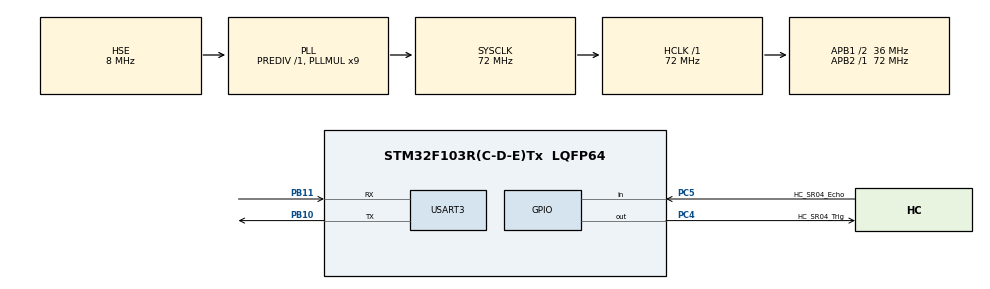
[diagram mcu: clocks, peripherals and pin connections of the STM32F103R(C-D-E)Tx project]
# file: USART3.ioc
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Dma.Request0=USART3_RX
Dma.Request1=USART3_TX
Dma.USART3_RX.0.Direction=DMA_PERIPH_TO_MEMORY
Dma.USART3_RX.0.Instance=DMA1_Channel3
Dma.USART3_RX.0.MemDataAlignment=DMA_MDATAALIGN_BYTE
Dma.USART3_RX.0.MemInc=DMA_MINC_ENABLE
Dma.USART3_RX.0.Mode=DMA_CIRCULAR
Dma.USART3_RX.0.PeriphDataAlignment=DMA_PDATAALIGN_BYTE
Dma.USART3_RX.0.PeriphInc=DMA_PINC_DISABLE
Dma.USART3_RX.0.Priority=DMA_PRIORITY_LOW
Dma.USART3_TX.1.Direction=DMA_MEMORY_TO_PERIPH
Dma.USART3_TX.1.Instance=DMA1_Channel2
Dma.USART3_TX.1.MemDataAlignment=DMA_MDATAALIGN_BYTE
Dma.USART3_TX.1.MemInc=DMA_MINC_ENABLE
Dma.USART3_TX.1.Mode=DMA_CIRCULAR
Dma.USART3_TX.1.PeriphDataAlignment=DMA_PDATAALIGN_BYTE
Dma.USART3_TX.1.PeriphInc=DMA_PINC_DISABLE
Dma.USART3_TX.1.Priority=DMA_PRIORITY_LOW
Mcu.Family=STM32F1
Mcu.Name=STM32F103R(C-D-E)Tx
Mcu.Package=LQFP64
NVIC.DMA1_Channel2_IRQn=true\:0\:0\:false\:false\:true\:false\:true
NVIC.DMA1_Channel3_IRQn=true\:0\:0\:false\:false\:true\:false\:true
NVIC.PriorityGroup=NVIC_PRIORITYGROUP_4
NVIC.TIM2_IRQn=true\:0\:0\:false\:false\:true\:true\:true
PA13.Mode=Serial_Wire
PA13.Signal=SYS_JTMS-SWDIO
PA14.Mode=Serial_Wire
PA14.Signal=SYS_JTCK-SWCLK
PB10.Mode=Asynchronous
PB10.Signal=USART3_TX
PB11.Mode=Asynchronous
PB11.Signal=USART3_RX
PC4.GPIO_Label=HC_SR04_Trig
PC4.GPIO_PuPd=GPIO_PULLDOWN
PC4.GPIO_Speed=GPIO_SPEED_FREQ_HIGH
PC4.Signal=GPIO_Output
PC5.GPIO_Label=HC_SR04_Echo
PC5.Signal=GPIO_Input
PD0-OSC_IN.Mode=HSE-External-Oscillator
PD0-OSC_IN.Signal=RCC_OSC_IN
PD1-OSC_OUT.Mode=HSE-External-Oscillator
PD1-OSC_OUT.Signal=RCC_OSC_OUT
ProjectManager.HeapSize=0x200
ProjectManager.StackSize=0x400
ProjectManager.TargetToolchain=STM32CubeIDE
RCC.AHBFreq_Value=72000000
RCC.APB1CLKDivider=RCC_HCLK_DIV2
RCC.APB1Freq_Value=36000000
RCC.APB1TimFreq_Value=72000000
RCC.APB2Freq_Value=72000000
RCC.APB2TimFreq_Value=72000000
RCC.HCLKFreq_Value=72000000
RCC.PLLMUL=RCC_PLL_MUL9
RCC.PLLSourceVirtual=RCC_PLLSOURCE_HSE
RCC.SYSCLKFreq_VALUE=72000000
RCC.SYSCLKSource=RCC_SYSCLKSOURCE_PLLCLK
RCC.USBFreq_Value=72000000
TIM2.Period=30000-1
TIM2.Prescaler=72-1
USART3.VirtualMode=VM_ASYNC
VP_TIM2_VS_ClockSourceINT.Mode=Internal
board=custom

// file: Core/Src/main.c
/* USER CODE BEGIN Header */
/**
 ******************************************************************************
 * @file           : main.c
 * @brief          : Main program body
 ******************************************************************************
 * @attention
 *
 * <h2><center>&copy; Copyright (c) 2021 STMicroelectronics.
 * All rights reserved.</center></h2>
 *
 * This software component is licensed by ST under BSD 3-Clause license,
 * the "License"; You may not use this file except in compliance with the
 * License. You may obtain a copy of the License at:
 *                        opensource.org/licenses/BSD-3-Clause
 *
 ******************************************************************************
 */
/* USER CODE END Header */
#include "main.h"
#include "dma.h"
#include "gpio.h"
#include "tim.h"
#include "usart.h"

/* USER CODE BEGIN Includes */
#include "echo.h"
/* USER CODE END Includes */

void SystemClock_Config(void);

int main(void) {
  /* USER CODE BEGIN 1 */
  uint32_t dta = 0;
  /* USER CODE END 1 */

  /* MCU Configuration--------------------------------------------------------*/

  /* Reset of all peripherals, Initializes the Flash interface and the Systick.
   */
  HAL_Init();

  /* Configure the system clock */
  SystemClock_Config();

  /* Initialize all configured peripherals */
  MX_GPIO_Init();
  MX_USART3_UART_Init();
  MX_DMA_Init();
  MX_TIM2_Init();
  /* USER CODE BEGIN 2 */
//  printf("\n\r UART Printf Example: retarget the C library printf function to "
//         "the UART\n\r");
  /* USER CODE END 2 */

  /* Infinite loop */
  while (1) {

    /* USER CODE BEGIN 3 */
    // printf("\n\r welcome to www.waveshere.com !!!\n\r");
    StartModule(); //启动超声波模块
    printf("超声波模块已启动\r\n");
    while (!GetStatus())
      ; //当ECHO返回0，等待
    start();
    while (GetStatus())
      ; //当ECHO为1计数并等待
    dta = get_num();
    printf("测试距离为：%d mm\r\n", dta);
    HAL_Delay(100); // 1000MS
  }
  /* USER CODE END 3 */
}

void SystemClock_Config(void) {
  RCC_OscInitTypeDef RCC_OscInitStruct = {0};
  RCC_ClkInitTypeDef RCC_ClkInitStruct = {0};

  /** Initializes the RCC Oscillators according to the specified parameters
   * in the RCC_OscInitTypeDef structure.
   */
  RCC_OscInitStruct.OscillatorType = RCC_OSCILLATORTYPE_HSE;
  RCC_OscInitStruct.HSEState = RCC_HSE_ON;
  RCC_OscInitStruct.HSEPredivValue = RCC_HSE_PREDIV_DIV1;
  RCC_OscInitStruct.HSIState = RCC_HSI_ON;
  RCC_OscInitStruct.PLL.PLLState = RCC_PLL_ON;
  RCC_OscInitStruct.PLL.PLLSource = RCC_PLLSOURCE_HSE;
  RCC_OscInitStruct.PLL.PLLMUL = RCC_PLL_MUL9;
  if (HAL_RCC_OscConfig(&RCC_OscInitStruct) != HAL_OK) {
    Error_Handler();
  }
  /** Initializes the CPU, AHB and APB buses clocks
   */
  RCC_ClkInitStruct.ClockType = RCC_CLOCKTYPE_HCLK | RCC_CLOCKTYPE_SYSCLK |
                                RCC_CLOCKTYPE_PCLK1 | RCC_CLOCKTYPE_PCLK2;
  RCC_ClkInitStruct.SYSCLKSource = RCC_SYSCLKSOURCE_PLLCLK;
  RCC_ClkInitStruct.AHBCLKDivider = RCC_SYSCLK_DIV1;
  RCC_ClkInitStruct.APB1CLKDivider = RCC_HCLK_DIV2;
  RCC_ClkInitStruct.APB2CLKDivider = RCC_HCLK_DIV1;

  if (HAL_RCC_ClockConfig(&RCC_ClkInitStruct, FLASH_LATENCY_2) != HAL_OK) {
    Error_Handler();
  }
}

void Error_Handler(void) {
  __disable_irq();
  while (1) {
  }
}

#ifdef USE_FULL_ASSERT
/**
 * @brief  Reports the name of the source file and the source line number
 *         where the assert_param error has occurred.
 * @param  file: pointer to the source file name
 * @param  line: assert_param error line source number
 * @retval None
 */
void assert_failed(uint8_t *file, uint32_t line) {
  /* USER CODE BEGIN 6 */
  /* User can add his own implementation to report the file name and line
     number,
     ex: printf("Wrong parameters value: file %s on line %d\r\n", file, line) */
  /* USER CODE END 6 */
}
#endif /* USE_FULL_ASSERT */

/************************ (C) COPYRIGHT STMicroelectronics *****END OF FILE****/
